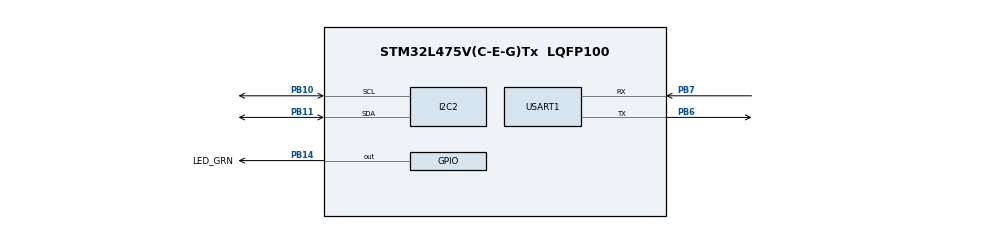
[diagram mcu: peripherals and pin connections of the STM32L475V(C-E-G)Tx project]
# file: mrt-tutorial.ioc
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Mcu.Family=STM32L4
Mcu.Name=STM32L475V(C-E-G)Tx
Mcu.Package=LQFP100
NVIC.PriorityGroup=NVIC_PRIORITYGROUP_4
NVIC.USART1_IRQn=true\:0\:0\:false\:false\:true\:true\:true
PB10.Mode=I2C
PB10.Signal=I2C2_SCL
PB11.Mode=I2C
PB11.Signal=I2C2_SDA
PB14.GPIO_Label=LED_GRN
PB14.Signal=GPIO_Output
PB6.Mode=Asynchronous
PB6.Signal=USART1_TX
PB7.Mode=Asynchronous
PB7.Signal=USART1_RX
ProjectManager.HeapSize=0x200
ProjectManager.StackSize=0x400
ProjectManager.TargetToolchain=STM32CubeIDE
RCC.HSE_VALUE=8000000
RCC.HSI_VALUE=16000000
RCC.LSE_VALUE=32768
RCC.MSI_VALUE=4000000
RCC.VCOOutputFreq_Value=32000000
USART1.VirtualMode-Asynchronous=VM_ASYNC
board=custom

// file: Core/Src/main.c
/* USER CODE BEGIN Header */
/**
  ******************************************************************************
  * @file           : main.c
  * @brief          : Main program body
  ******************************************************************************
  * @attention
  *
  * <h2><center>&copy; Copyright (c) 2020 STMicroelectronics.
  * All rights reserved.</center></h2>
  *
  * This software component is licensed by ST under BSD 3-Clause license,
  * the "License"; You may not use this file except in compliance with the
  * License. You may obtain a copy of the License at:
  *                        opensource.org/licenses/BSD-3-Clause
  *
  ******************************************************************************
  */
/* USER CODE END Header */

#include "main.h"

/* USER CODE BEGIN Includes */
#include "Platforms/Common/mrt_platform.h" /* This will include the stm32 layer based on the MRT_PLATFORM symbol we set*/
/* USER CODE END Includes */

I2C_HandleTypeDef hi2c2;

UART_HandleTypeDef huart1;

void SystemClock_Config(void);
static void MX_GPIO_Init(void);
static void MX_I2C2_Init(void);
static void MX_USART1_UART_Init(void);

int main(void)
{

  /* MCU Configuration--------------------------------------------------------*/

  /* Reset of all peripherals, Initializes the Flash interface and the Systick. */
  HAL_Init();

  /* Configure the system clock */
  SystemClock_Config();

  /* Initialize all configured peripherals */
  MX_GPIO_Init();
  MX_I2C2_Init();
  MX_USART1_UART_Init();

  /* Infinite loop */
  while (1)
  {
  	/** STM32 HAL does not have a type for pins, all of its functions use (port,pin). MRT_GPIO() is a macro that wraps them
  	  * This is so that device drivers have a single struct for pins
  	  */
  	MRT_GPIO_WRITE(MRT_GPIO(LED_GRN),HIGH);     //set the pin high
  	MRT_DELAY_MS(1000);                         //wait 1000 ms
  	MRT_GPIO_WRITE(MRT_GPIO(LED_GRN),LOW);      //set the pin low
  	MRT_DELAY_MS(1000);                         //wait 1000 ms
  }
}

void SystemClock_Config(void)
{
  RCC_OscInitTypeDef RCC_OscInitStruct = {0};
  RCC_ClkInitTypeDef RCC_ClkInitStruct = {0};
  RCC_PeriphCLKInitTypeDef PeriphClkInit = {0};

  /** Initializes the CPU, AHB and APB busses clocks
  */
  RCC_OscInitStruct.OscillatorType = RCC_OSCILLATORTYPE_MSI;
  RCC_OscInitStruct.MSIState = RCC_MSI_ON;
  RCC_OscInitStruct.MSICalibrationValue = 0;
  RCC_OscInitStruct.MSIClockRange = RCC_MSIRANGE_6;
  RCC_OscInitStruct.PLL.PLLState = RCC_PLL_NONE;
  if (HAL_RCC_OscConfig(&RCC_OscInitStruct) != HAL_OK)
  {
    Error_Handler();
  }
  /** Initializes the CPU, AHB and APB busses clocks
  */
  RCC_ClkInitStruct.ClockType = RCC_CLOCKTYPE_HCLK|RCC_CLOCKTYPE_SYSCLK
                              |RCC_CLOCKTYPE_PCLK1|RCC_CLOCKTYPE_PCLK2;
  RCC_ClkInitStruct.SYSCLKSource = RCC_SYSCLKSOURCE_MSI;
  RCC_ClkInitStruct.AHBCLKDivider = RCC_SYSCLK_DIV1;
  RCC_ClkInitStruct.APB1CLKDivider = RCC_HCLK_DIV1;
  RCC_ClkInitStruct.APB2CLKDivider = RCC_HCLK_DIV1;

  if (HAL_RCC_ClockConfig(&RCC_ClkInitStruct, FLASH_LATENCY_0) != HAL_OK)
  {
    Error_Handler();
  }
  PeriphClkInit.PeriphClockSelection = RCC_PERIPHCLK_USART1|RCC_PERIPHCLK_I2C2;
  PeriphClkInit.Usart1ClockSelection = RCC_USART1CLKSOURCE_PCLK2;
  PeriphClkInit.I2c2ClockSelection = RCC_I2C2CLKSOURCE_PCLK1;
  if (HAL_RCCEx_PeriphCLKConfig(&PeriphClkInit) != HAL_OK)
  {
    Error_Handler();
  }
  /** Configure the main internal regulator output voltage
  */
  if (HAL_PWREx_ControlVoltageScaling(PWR_REGULATOR_VOLTAGE_SCALE1) != HAL_OK)
  {
    Error_Handler();
  }
}

static void MX_I2C2_Init(void)
{

  hi2c2.Instance = I2C2;
  hi2c2.Init.Timing = 0x00000E14;
  hi2c2.Init.OwnAddress1 = 0;
  hi2c2.Init.AddressingMode = I2C_ADDRESSINGMODE_7BIT;
  hi2c2.Init.DualAddressMode = I2C_DUALADDRESS_DISABLE;
  hi2c2.Init.OwnAddress2 = 0;
  hi2c2.Init.OwnAddress2Masks = I2C_OA2_NOMASK;
  hi2c2.Init.GeneralCallMode = I2C_GENERALCALL_DISABLE;
  hi2c2.Init.NoStretchMode = I2C_NOSTRETCH_DISABLE;
  if (HAL_I2C_Init(&hi2c2) != HAL_OK)
  {
    Error_Handler();
  }
  /** Configure Analogue filter
  */
  if (HAL_I2CEx_ConfigAnalogFilter(&hi2c2, I2C_ANALOGFILTER_ENABLE) != HAL_OK)
  {
    Error_Handler();
  }
  /** Configure Digital filter
  */
  if (HAL_I2CEx_ConfigDigitalFilter(&hi2c2, 0) != HAL_OK)
  {
    Error_Handler();
  }

}

static void MX_USART1_UART_Init(void)
{

  huart1.Instance = USART1;
  huart1.Init.BaudRate = 115200;
  huart1.Init.WordLength = UART_WORDLENGTH_8B;
  huart1.Init.StopBits = UART_STOPBITS_1;
  huart1.Init.Parity = UART_PARITY_NONE;
  huart1.Init.Mode = UART_MODE_TX_RX;
  huart1.Init.HwFlowCtl = UART_HWCONTROL_NONE;
  huart1.Init.OverSampling = UART_OVERSAMPLING_16;
  huart1.Init.OneBitSampling = UART_ONE_BIT_SAMPLE_DISABLE;
  huart1.AdvancedInit.AdvFeatureInit = UART_ADVFEATURE_NO_INIT;
  if (HAL_UART_Init(&huart1) != HAL_OK)
  {
    Error_Handler();
  }

}

static void MX_GPIO_Init(void)
{
  GPIO_InitTypeDef GPIO_InitStruct = {0};

  /* GPIO Ports Clock Enable */
  __HAL_RCC_GPIOB_CLK_ENABLE();

  /*Configure GPIO pin Output Level */
  HAL_GPIO_WritePin(LED_GRN_GPIO_Port, LED_GRN_Pin, GPIO_PIN_RESET);

  /*Configure GPIO pin : LED_GRN_Pin */
  GPIO_InitStruct.Pin = LED_GRN_Pin;
  GPIO_InitStruct.Mode = GPIO_MODE_OUTPUT_PP;
  GPIO_InitStruct.Pull = GPIO_NOPULL;
  GPIO_InitStruct.Speed = GPIO_SPEED_FREQ_LOW;
  HAL_GPIO_Init(LED_GRN_GPIO_Port, &GPIO_InitStruct);

}

void Error_Handler(void)
{
}

/************************ (C) COPYRIGHT STMicroelectronics *****END OF FILE****/
